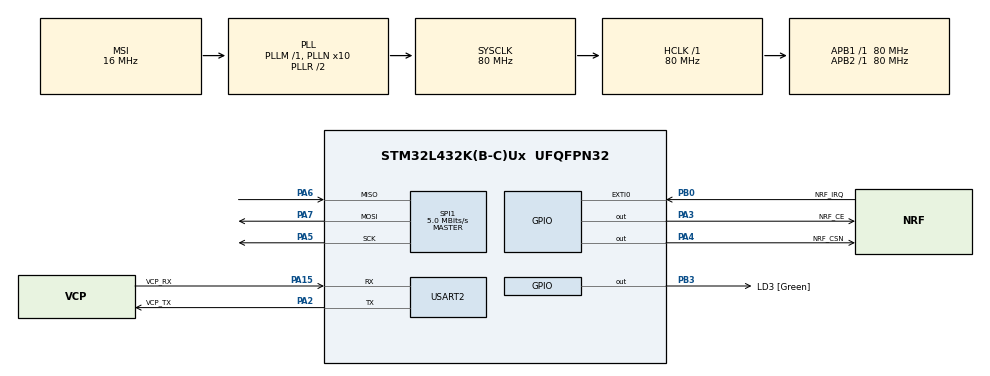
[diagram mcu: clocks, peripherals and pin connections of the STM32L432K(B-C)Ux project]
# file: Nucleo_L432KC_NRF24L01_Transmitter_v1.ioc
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Mcu.Family=STM32L4
PA6.Mode=Full_Duplex_Master
RCC.CortexFreq_Value=80000000
SPI1.VirtualType=VM_MASTER
PA0.GPIO_Label=MCO [High speed clock in]
PB0.GPIO_Label=NRF_IRQ
PA15\ (JTDI).Signal=USART2_RX
PC15-OSC32_OUT\ (PC15).Mode=LSE-External-Oscillator
PA3.GPIO_Speed=GPIO_SPEED_FREQ_VERY_HIGH
RCC.SYSCLKSource=RCC_SYSCLKSOURCE_PLLCLK
ProjectManager.StackSize=0x400
PB3\ (JTDO-TRACESWO).Signal=GPIO_Output
PC14-OSC32_IN\ (PC14).Mode=LSE-External-Oscillator
PA14\ (JTCK-SWCLK).Signal=SYS_JTCK-SWCLK
PA15\ (JTDI).Mode=Asynchronous
SPI1.Direction=SPI_DIRECTION_2LINES
RCC.HCLKFreq_Value=80000000
RCC.APB2TimFreq_Value=80000000
SPI1.CalculateBaudRate=5.0 MBits/s
RCC.AHBFreq_Value=80000000
RCC.HSE_VALUE=8000000
USART2.VirtualMode-Asynchronous=VM_ASYNC
RCC.PLLMUL=RCC_PLLMUL_4
PA4.GPIO_Speed=GPIO_SPEED_FREQ_VERY_HIGH
PB0.GPIO_ModeDefaultEXTI=GPIO_MODE_IT_FALLING
SPI1.DataSize=SPI_DATASIZE_8BIT
PA0.Mode=HSE-External-Clock-Source-for-LittleOrca
PA0.Signal=RCC_CK_IN
Mcu.Package=UFQFPN32
PA6.Signal=SPI1_MISO
PA2.GPIO_Label=VCP_TX
RCC.APB1TimFreq_Value=80000000
PA13\ (JTMS-SWDIO).Signal=SYS_JTMS-SWDIO
SPI1.BaudRatePrescaler=SPI_BAUDRATEPRESCALER_16
PA4.GPIO_Label=NRF_CSN
RCC.MSIClockRange=RCC_MSIRANGE_8
RCC.HSI48_VALUE=48000000
PA3.Signal=GPIO_Output
PA5.Mode=Full_Duplex_Master
RCC.MSI_VALUE=16000000
PA14\ (JTCK-SWCLK).Mode=Serial_Wire
PA7.Mode=Full_Duplex_Master
PC15-OSC32_OUT\ (PC15).Signal=RCC_OSC32_OUT
PA14\ (JTCK-SWCLK).GPIO_Label=SWCLK
PB3\ (JTDO-TRACESWO).GPIO_Label=LD3 [Green]
RCC.HSI16_VALUE=16000000
PA4.PinState=GPIO_PIN_SET
ProjectManager.TargetToolchain=STM32CubeIDE
RCC.USBFreq_Value=64000000
PA5.Signal=SPI1_SCK
board=NUCLEO-L432KC
RCC.VCOOutputFreq_Value=160000000
RCC.APB2Freq_Value=80000000
SPI1.CRCCalculation=SPI_CRCCALCULATION_DISABLE
PA13\ (JTMS-SWDIO).GPIO_Label=SWDIO
SPI1.Mode=SPI_MODE_MASTER
RCC.ADCFreq_Value=64000000
PA15\ (JTDI).GPIO_Label=VCP_RX
Mcu.Name=STM32L432K(B-C)Ux
SPI1.NSSPMode=SPI_NSS_PULSE_DISABLE
PA2.Signal=USART2_TX
PA13\ (JTMS-SWDIO).Mode=Serial_Wire
NVIC.EXTI0_IRQn=true\:0\:0\:false\:false\:true\:true\:true
PA4.Signal=GPIO_Output
RCC.SYSCLKFreq_VALUE=80000000
PC14-OSC32_IN\ (PC14).Signal=RCC_OSC32_IN
ProjectManager.HeapSize=0x200
RCC.HSI_VALUE=16000000
NVIC.PriorityGroup=NVIC_PRIORITYGROUP_4
RCC.PLLN=10
PA2.Mode=Asynchronous
PA3.PinState=GPIO_PIN_RESET
RCC.APB1Freq_Value=80000000
PB0.Signal=GPXTI0
PB0.GPIO_PuPd=GPIO_PULLUP
PA3.GPIO_Label=NRF_CE
PA7.Signal=SPI1_MOSI

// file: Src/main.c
/* USER CODE BEGIN Header */
/**
  ******************************************************************************
  * @file           : main.c
  * @brief          : Main program body
  ******************************************************************************
  ** This notice applies to any and all portions of this file
  * that are not between comment pairs USER CODE BEGIN and
  * USER CODE END. Other portions of this file, whether
  * inserted by the user or by software development tools
  * are owned by their respective copyright owners.
  *
  * COPYRIGHT(c) 2018 STMicroelectronics
  *
  * Redistribution and use in source and binary forms, with or without modification,
  * are permitted provided that the following conditions are met:
  *   1. Redistributions of source code must retain the above copyright notice,
  *      this list of conditions and the following disclaimer.
  *   2. Redistributions in binary form must reproduce the above copyright notice,
  *      this list of conditions and the following disclaimer in the documentation
  *      and/or other materials provided with the distribution.
  *   3. Neither the name of STMicroelectronics nor the names of its contributors
  *      may be used to endorse or promote products derived from this software
  *      without specific prior written permission.
  *
  * THIS SOFTWARE IS PROVIDED BY THE COPYRIGHT HOLDERS AND CONTRIBUTORS "AS IS"
  * AND ANY EXPRESS OR IMPLIED WARRANTIES, INCLUDING, BUT NOT LIMITED TO, THE
  * IMPLIED WARRANTIES OF MERCHANTABILITY AND FITNESS FOR A PARTICULAR PURPOSE ARE
  * DISCLAIMED. IN NO EVENT SHALL THE COPYRIGHT HOLDER OR CONTRIBUTORS BE LIABLE
  * FOR ANY DIRECT, INDIRECT, INCIDENTAL, SPECIAL, EXEMPLARY, OR CONSEQUENTIAL
  * DAMAGES (INCLUDING, BUT NOT LIMITED TO, PROCUREMENT OF SUBSTITUTE GOODS OR
  * SERVICES; LOSS OF USE, DATA, OR PROFITS; OR BUSINESS INTERRUPTION) HOWEVER
  * CAUSED AND ON ANY THEORY OF LIABILITY, WHETHER IN CONTRACT, STRICT LIABILITY,
  * OR TORT (INCLUDING NEGLIGENCE OR OTHERWISE) ARISING IN ANY WAY OUT OF THE USE
  * OF THIS SOFTWARE, EVEN IF ADVISED OF THE POSSIBILITY OF SUCH DAMAGE.
  *
  ******************************************************************************
  */
/* USER CODE END Header */
#include "main.h"

SPI_HandleTypeDef hspi1;

UART_HandleTypeDef huart2;

void SystemClock_Config(void);
static void MX_GPIO_Init(void);
static void MX_USART2_UART_Init(void);
static void MX_SPI1_Init(void);
/* USER CODE BEGIN PFP */
void runRadio(void);

/* USER CODE END PFP */

int main(void)
{

  /* MCU Configuration--------------------------------------------------------*/

  /* Reset of all peripherals, Initializes the Flash interface and the Systick. */
  HAL_Init();

  /* Configure the system clock */
  SystemClock_Config();

  /* Initialize all configured peripherals */
  MX_GPIO_Init();
  MX_USART2_UART_Init();
  MX_SPI1_Init();
  /* USER CODE BEGIN 2 */

  if (HAL_SPIEx_FlushRxFifo(&hspi1) != HAL_OK){
	  Error_Handler();
  }

  /* USER CODE END 2 */

  /* Infinite loop */
  /* USER CODE BEGIN WHILE */
  runRadio();
    /* USER CODE END WHILE */

}

void SystemClock_Config(void)
{
  RCC_OscInitTypeDef RCC_OscInitStruct = {0};
  RCC_ClkInitTypeDef RCC_ClkInitStruct = {0};
  RCC_PeriphCLKInitTypeDef PeriphClkInit = {0};

  /** Configure LSE Drive Capability
  */
  HAL_PWR_EnableBkUpAccess();
  __HAL_RCC_LSEDRIVE_CONFIG(RCC_LSEDRIVE_LOW);
  /** Initializes the RCC Oscillators according to the specified parameters
  * in the RCC_OscInitTypeDef structure.
  */
  RCC_OscInitStruct.OscillatorType = RCC_OSCILLATORTYPE_LSE|RCC_OSCILLATORTYPE_MSI;
  RCC_OscInitStruct.LSEState = RCC_LSE_ON;
  RCC_OscInitStruct.MSIState = RCC_MSI_ON;
  RCC_OscInitStruct.MSICalibrationValue = 0;
  RCC_OscInitStruct.MSIClockRange = RCC_MSIRANGE_8;
  RCC_OscInitStruct.PLL.PLLState = RCC_PLL_ON;
  RCC_OscInitStruct.PLL.PLLSource = RCC_PLLSOURCE_MSI;
  RCC_OscInitStruct.PLL.PLLM = 1;
  RCC_OscInitStruct.PLL.PLLN = 10;
  RCC_OscInitStruct.PLL.PLLP = RCC_PLLP_DIV7;
  RCC_OscInitStruct.PLL.PLLQ = RCC_PLLQ_DIV2;
  RCC_OscInitStruct.PLL.PLLR = RCC_PLLR_DIV2;
  if (HAL_RCC_OscConfig(&RCC_OscInitStruct) != HAL_OK)
  {
    Error_Handler();
  }
  /** Initializes the CPU, AHB and APB buses clocks
  */
  RCC_ClkInitStruct.ClockType = RCC_CLOCKTYPE_HCLK|RCC_CLOCKTYPE_SYSCLK
                              |RCC_CLOCKTYPE_PCLK1|RCC_CLOCKTYPE_PCLK2;
  RCC_ClkInitStruct.SYSCLKSource = RCC_SYSCLKSOURCE_PLLCLK;
  RCC_ClkInitStruct.AHBCLKDivider = RCC_SYSCLK_DIV1;
  RCC_ClkInitStruct.APB1CLKDivider = RCC_HCLK_DIV1;
  RCC_ClkInitStruct.APB2CLKDivider = RCC_HCLK_DIV1;

  if (HAL_RCC_ClockConfig(&RCC_ClkInitStruct, FLASH_LATENCY_4) != HAL_OK)
  {
    Error_Handler();
  }
  PeriphClkInit.PeriphClockSelection = RCC_PERIPHCLK_USART2;
  PeriphClkInit.Usart2ClockSelection = RCC_USART2CLKSOURCE_PCLK1;
  if (HAL_RCCEx_PeriphCLKConfig(&PeriphClkInit) != HAL_OK)
  {
    Error_Handler();
  }
  /** Configure the main internal regulator output voltage
  */
  if (HAL_PWREx_ControlVoltageScaling(PWR_REGULATOR_VOLTAGE_SCALE1) != HAL_OK)
  {
    Error_Handler();
  }
  /** Enable MSI Auto calibration
  */
  HAL_RCCEx_EnableMSIPLLMode();
}

static void MX_SPI1_Init(void)
{

  /* SPI1 parameter configuration*/
  hspi1.Instance = SPI1;
  hspi1.Init.Mode = SPI_MODE_MASTER;
  hspi1.Init.Direction = SPI_DIRECTION_2LINES;
  hspi1.Init.DataSize = SPI_DATASIZE_8BIT;
  hspi1.Init.CLKPolarity = SPI_POLARITY_LOW;
  hspi1.Init.CLKPhase = SPI_PHASE_1EDGE;
  hspi1.Init.NSS = SPI_NSS_SOFT;
  hspi1.Init.BaudRatePrescaler = SPI_BAUDRATEPRESCALER_16;
  hspi1.Init.FirstBit = SPI_FIRSTBIT_MSB;
  hspi1.Init.TIMode = SPI_TIMODE_DISABLE;
  hspi1.Init.CRCCalculation = SPI_CRCCALCULATION_DISABLE;
  hspi1.Init.CRCPolynomial = 7;
  hspi1.Init.CRCLength = SPI_CRC_LENGTH_DATASIZE;
  hspi1.Init.NSSPMode = SPI_NSS_PULSE_DISABLE;
  if (HAL_SPI_Init(&hspi1) != HAL_OK)
  {
    Error_Handler();
  }

}

static void MX_USART2_UART_Init(void)
{

  huart2.Instance = USART2;
  huart2.Init.BaudRate = 115200;
  huart2.Init.WordLength = UART_WORDLENGTH_8B;
  huart2.Init.StopBits = UART_STOPBITS_1;
  huart2.Init.Parity = UART_PARITY_NONE;
  huart2.Init.Mode = UART_MODE_TX_RX;
  huart2.Init.HwFlowCtl = UART_HWCONTROL_NONE;
  huart2.Init.OverSampling = UART_OVERSAMPLING_16;
  huart2.Init.OneBitSampling = UART_ONE_BIT_SAMPLE_DISABLE;
  huart2.AdvancedInit.AdvFeatureInit = UART_ADVFEATURE_NO_INIT;
  if (HAL_UART_Init(&huart2) != HAL_OK)
  {
    Error_Handler();
  }

}

static void MX_GPIO_Init(void)
{
  GPIO_InitTypeDef GPIO_InitStruct = {0};

  /* GPIO Ports Clock Enable */
  __HAL_RCC_GPIOC_CLK_ENABLE();
  __HAL_RCC_GPIOA_CLK_ENABLE();
  __HAL_RCC_GPIOB_CLK_ENABLE();
  __HAL_RCC_GPIOH_CLK_ENABLE();

  /*Configure GPIO pin Output Level */
  HAL_GPIO_WritePin(NRF_CE_GPIO_Port, NRF_CE_Pin, GPIO_PIN_RESET);

  /*Configure GPIO pin Output Level */
  HAL_GPIO_WritePin(NRF_CSN_GPIO_Port, NRF_CSN_Pin, GPIO_PIN_SET);

  /*Configure GPIO pin Output Level */
  HAL_GPIO_WritePin(LD3_GPIO_Port, LD3_Pin, GPIO_PIN_RESET);

  /*Configure GPIO pins : PA1 PA8 PA9 PA10
                           PA11 PA12 */
  GPIO_InitStruct.Pin = GPIO_PIN_1|GPIO_PIN_8|GPIO_PIN_9|GPIO_PIN_10
                          |GPIO_PIN_11|GPIO_PIN_12;
  GPIO_InitStruct.Mode = GPIO_MODE_ANALOG;
  GPIO_InitStruct.Pull = GPIO_NOPULL;
  HAL_GPIO_Init(GPIOA, &GPIO_InitStruct);

  /*Configure GPIO pins : NRF_CE_Pin NRF_CSN_Pin */
  GPIO_InitStruct.Pin = NRF_CE_Pin|NRF_CSN_Pin;
  GPIO_InitStruct.Mode = GPIO_MODE_OUTPUT_PP;
  GPIO_InitStruct.Pull = GPIO_NOPULL;
  GPIO_InitStruct.Speed = GPIO_SPEED_FREQ_VERY_HIGH;
  HAL_GPIO_Init(GPIOA, &GPIO_InitStruct);

  /*Configure GPIO pin : NRF_IRQ_Pin */
  GPIO_InitStruct.Pin = NRF_IRQ_Pin;
  GPIO_InitStruct.Mode = GPIO_MODE_IT_FALLING;
  GPIO_InitStruct.Pull = GPIO_PULLUP;
  HAL_GPIO_Init(NRF_IRQ_GPIO_Port, &GPIO_InitStruct);

  /*Configure GPIO pins : PB1 PB4 PB5 PB6
                           PB7 */
  GPIO_InitStruct.Pin = GPIO_PIN_1|GPIO_PIN_4|GPIO_PIN_5|GPIO_PIN_6
                          |GPIO_PIN_7;
  GPIO_InitStruct.Mode = GPIO_MODE_ANALOG;
  GPIO_InitStruct.Pull = GPIO_NOPULL;
  HAL_GPIO_Init(GPIOB, &GPIO_InitStruct);

  /*Configure GPIO pin : LD3_Pin */
  GPIO_InitStruct.Pin = LD3_Pin;
  GPIO_InitStruct.Mode = GPIO_MODE_OUTPUT_PP;
  GPIO_InitStruct.Pull = GPIO_NOPULL;
  GPIO_InitStruct.Speed = GPIO_SPEED_FREQ_LOW;
  HAL_GPIO_Init(LD3_GPIO_Port, &GPIO_InitStruct);

  /*Configure GPIO pin : PH3 */
  GPIO_InitStruct.Pin = GPIO_PIN_3;
  GPIO_InitStruct.Mode = GPIO_MODE_ANALOG;
  GPIO_InitStruct.Pull = GPIO_NOPULL;
  HAL_GPIO_Init(GPIOH, &GPIO_InitStruct);

  /* EXTI interrupt init*/
  HAL_NVIC_SetPriority(EXTI0_IRQn, 0, 0);
  HAL_NVIC_EnableIRQ(EXTI0_IRQn);

}

void Error_Handler(void)
{
}

/************************ (C) COPYRIGHT STMicroelectronics *****END OF FILE****/
